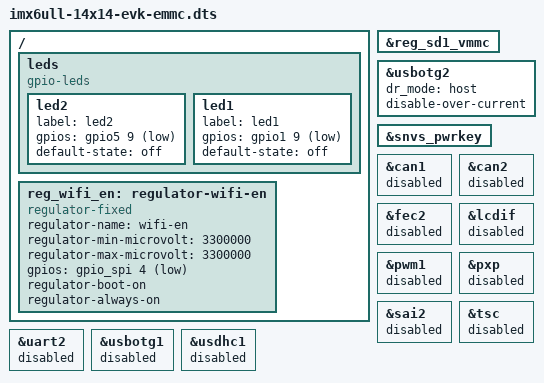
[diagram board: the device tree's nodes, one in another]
/*
 * Copyright 2019 NXP
 */
#include "imx6ull-14x14-evk.dts"

/ {
	leds {
		compatible = "gpio-leds";
		pinctrl-names = "default";
		status = "okay";

		led2 {
			label = "led2";
			gpios = <&gpio5 9 GPIO_ACTIVE_LOW>;
			default-state = "off";
			
		};
		led1 {
			label = "led1";
			gpios = <&gpio1 9 GPIO_ACTIVE_LOW>;
			default-state = "off";
		};
	};

	reg_wifi_en: regulator-wifi-en {
		compatible = "regulator-fixed";
		regulator-name = "wifi-en";
		regulator-min-microvolt = <3300000>;
		regulator-max-microvolt = <3300000>;
		gpios = <&gpio_spi 4 GPIO_ACTIVE_LOW>;
		regulator-boot-on;
		regulator-always-on;
	};
};

&reg_sd1_vmmc {
	/delete-property/ gpio;
	/delete-property/ enable-active-high;
	/delete-property/ off-on-delay-us;
};

&usbotg2 {
	dr_mode = "host";
	disable-over-current;
	status = "okay";
};

&snvs_pwrkey {
	status = "okay";
};

&can1   { status = "disabled"; };
&can2   { status = "disabled"; };
&fec2   { status = "disabled"; };
&lcdif  { status = "disabled"; };
&pwm1   { status = "disabled"; };
&pxp    { status = "disabled"; };
&sai2   { status = "disabled"; };
&tsc    { status = "disabled"; };
&uart2  { status = "disabled"; };
&usbotg1 { status = "disabled"; };
&usdhc1 { status = "disabled"; };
